AUTOSAR XML (schema 4-0-3)
package /ComponentTypes
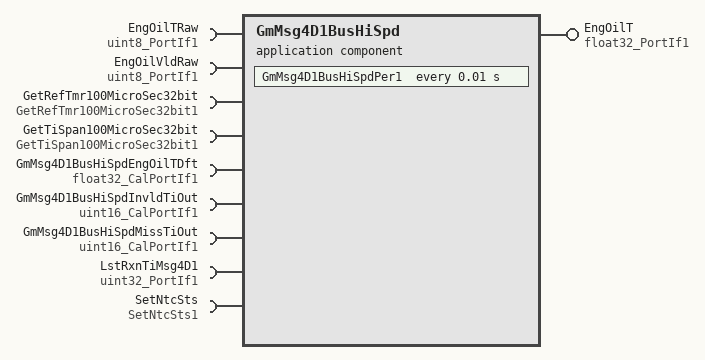
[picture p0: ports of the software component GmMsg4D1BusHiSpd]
  application sw component type GmMsg4D1BusHiSpd
    provide port EngOilT: nonqueued-sender-com-spec{data-element=Val, init-value=0}, provided-interface=float32_PortIf1
    9 x require port:
      EngOilTRaw: nonqueued-receiver-com-spec{data-element=Val, filter=data-filter-type=ALWAYS, init-value=0}, required-interface=uint8_PortIf1
      EngOilVldRaw: nonqueued-receiver-com-spec{data-element=Val, filter=data-filter-type=ALWAYS, init-value=0}, required-interface=uint8_PortIf1
      GetRefTmr100MicroSec32bit: required-interface=GetRefTmr100MicroSec32bit1
      GetTiSpan100MicroSec32bit: required-interface=GetTiSpan100MicroSec32bit1
      GmMsg4D1BusHiSpdEngOilTDft: parameter-require-com-spec{init-value=60, parameter=Val}, required-interface=float32_CalPortIf1
      GmMsg4D1BusHiSpdInvldTiOut: parameter-require-com-spec{init-value=5000, parameter=Val}, required-interface=uint16_CalPortIf1
      GmMsg4D1BusHiSpdMissTiOut: parameter-require-com-spec{init-value=500, parameter=Val}, required-interface=uint16_CalPortIf1
      LstRxnTiMsg4D1: nonqueued-receiver-com-spec{data-element=Val, filter=data-filter-type=ALWAYS, init-value=0}, required-interface=uint32_PortIf1
      SetNtcSts: required-interface=SetNtcSts1
    behavior GmMsg4D1BusHiSpd_InternalBehavior: data-type-mapping=Nexteer
      ar-typed-per-instance-memorys:
        data GmMsg4D1BusHiSpdInvldMsgTmr: sw-calibration-access=READ-ONLY, type=uint32
      timing event TMT_GM0C9HSPer1: start-on-event=GmMsg4D1BusHiSpdPer1, period=0.01
      runnable GmMsg4D1BusHiSpdPer1
        data-receive-point-by-arguments:
          access REC_EngCooltT_Val: accessed-variable=EngOilTRaw.Val
          access REC_EngCooltVld_Val: accessed-variable=EngOilVldRaw.Val
          access REC_Msg4C1HSLstRxnTi_Val: accessed-variable=LstRxnTiMsg4D1.Val
        data-send-points:
          access SEND_GM4C1HSEngT_Val: accessed-variable=EngOilT.Val
        sync call SC_GetRefTmr100MicroSec32bit_Oper: operation=GetRefTmr100MicroSec32bit.Oper, timeout=0
        sync call SC_GetTiSpan100MicroSec32bit_Oper: operation=GetTiSpan100MicroSec32bit.Oper, timeout=0
        sync call SC_SetNtcSts_Oper: operation=SetNtcSts.Oper, timeout=0
  swc implementation GmMsg4D1BusHiSpd_Implementation: behavior=GmMsg4D1BusHiSpd_InternalBehavior
    code-descriptors:
      code Default: artifact-descriptors=autosar-engineering-object={short-label=Default, category=SWSRC}
